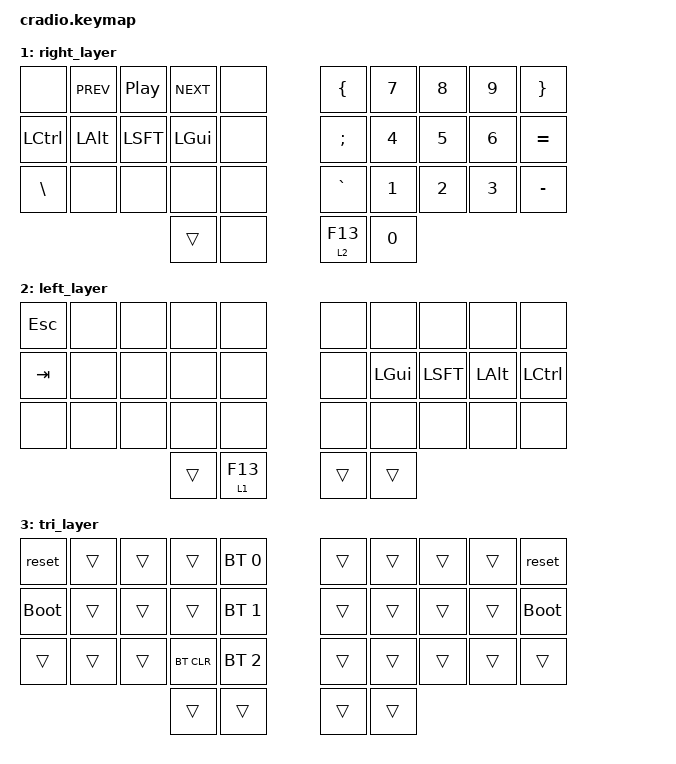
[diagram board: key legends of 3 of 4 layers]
// Copyright (c) 2022 The ZMK Contributors
// SPDX-License-Identifier: MIT

#include <behaviors.dtsi>
#include <dt-bindings/zmk/keys.h>
#include <dt-bindings/zmk/bt.h>

// Home row mods macro
#define HRML(k1,k2,k3,k4) &ht LCTRL k1  &ht LALT k2  &ht LSHFT k3  &ht LGUI k4
#define HRMR(k1,k2,k3,k4) &ht LGUI k1  &ht LSHFT k2  &ht LALT k3  &ht LCTRL k4

/ {
    behaviors {
        ht: hold_tap {
            label = "hold_tap";
            compatible = "zmk,behavior-hold-tap";
            #binding-cells = <2>;
            flavor = "tap-preferred";
            tapping-term-ms = <220>;
            quick-tap-ms = <150>;
            global-quick-tap;
            bindings = <&kp>, <&kp>;
        };
    };

    combos {
    	   compatible = "zmk,combos";
	   
 	   combo_coln {
	       key-positions = <20 21>;
	       bindings = <&kp COLON>;
	   };
 	   combo_mins {
	       key-positions = <22 23>;
	       bindings = <&kp MINUS>;
	   };
 	   combo_uscr {
	       key-positions = <26 27>;
	       bindings = <&kp UNDERSCORE>;
	   };
 	   combo_scln {
	       key-positions = <28 29>;
	       bindings = <&kp MINUS>;
	   };
	   
 	   combo_lbrc {
	       key-positions = <2 12>;
	       bindings = <&kp LBRC>;
	   };
 	   combo_lpar{
	       key-positions = <3 13>;
	       bindings = <&kp LPRN>;
	   };
 	   combo_lbkt {
	       key-positions = <4 14>;
	       bindings = <&kp LBKT>;
	   };
 	   combo_rbkt {
	       key-positions = <5 15>;
	       bindings = <&kp RBKT>;
	   };
 	   combo_rpar {
	       key-positions = <6 16>;
	       bindings = <&kp RPRN>;
	   };
 	   combo_rbrc {
	       key-positions = <7 17>;
	       bindings = <&kp RBRC>;
	   };
    };

    conditional_layers {
        compatible = "zmk,conditional-layers";
        tri_layer {
            if-layers = <1 2>;
            then-layer = <3>;
        };
    };

    keymap {
        compatible = "zmk,keymap";
        default_layer {
            bindings = <
        // //╭──────────┬──────────┬──────────┬──────────┬──────────╮   ╭──────────┬──────────┬──────────┬──────────┬──────────╮
        // //│  Q       │  W       │  E       │  R       │  T       │   │  Y       │  U       │  I       │  O       │  P       │
        //     &kp Q      &kp W      &kp E      &kp R      &kp T          &kp Y      &kp U      &kp I      &kp O      &kp P
        // //├──────────┼──────────┼──────────┼──────────┼──────────┤   ├──────────┼──────────┼──────────┼──────────┼──────────┤
        // //│  A       │  S       │  D       │  F       │  G       │   │  H       │  J       │  K       │  L       │ ' "      │
        //     HRML(A,        S,         D,         F)     &kp G          &kp H      HRMR(J,        K,         L,        SQT)
        // //├──────────┼──────────┼──────────┼──────────┼──────────┤   ├──────────┼──────────┼──────────┼──────────┼──────────┤
        // //│  Z       │  X       │  C       │  V       │  B       │   │  N       │  M       │ , <      │ . >      │ / ?      │
        //     &kp Z      &kp X      &kp C      &kp V      &kp B          &kp N      &kp M      &kp COMMA  &kp DOT    &kp FSLH
        // //╰──────────┴──────────┴──────────┼──────────┼──────────┤   ├──────────┼──────────┼──────────┴──────────┴──────────╯
        //                                     &kp LSHFT   &lt 1 BSPC    &lt 2 SPACE  &ht LALT ENTER
        // //                                 ╰──────────┴──────────╯   ╰──────────┴──────────╯

        //╭──────────┬──────────┬──────────┬──────────┬──────────╮   ╭──────────┬──────────┬──────────┬──────────┬──────────╮
            &kp Q      &kp W      &kp F      &kp P      &kp B          &kp J      &kp L      &kp U      &kp Y      &kp SQT
        //├──────────┼──────────┼──────────┼──────────┼──────────┤   ├──────────┼──────────┼──────────┼──────────┼──────────┤
            HRML(A,        R,         S,         T)     &kp G          &kp M      HRMR(N,        E,         I,        O)
        //├──────────┼──────────┼──────────┼──────────┼──────────┤   ├──────────┼──────────┼──────────┼──────────┼──────────┤
            &kp Z      &kp X      &kp C      &kp D      &kp V          &kp K      &kp H      &kp COMMA  &kp DOT    &kp FSLH
        //╰──────────┴──────────┴──────────┼──────────┼──────────┤   ├──────────┼──────────┼──────────┴──────────┴──────────╯
                                            &kp LSHFT   &lt 1 BSPC    &lt 2 SPACE  &ht LALT ENTER
        //                                 ╰──────────┴──────────╯   ╰──────────┴──────────╯
            >;
        };

        right_layer {
            bindings = <
        //╭──────────┬──────────┬──────────┬──────────┬──────────╮   ╭──────────┬──────────┬──────────┬──────────┬──────────╮
            &none      &kp C_PREV &kp C_PP   &kp C_NEXT &none          &kp LBRC   &kp N7     &kp N8     &kp N9     &kp RBRC
        //├──────────┼──────────┼──────────┼──────────┼──────────┤   ├──────────┼──────────┼──────────┼──────────┼──────────┤
            &kp LCTL   &kp LALT   &kp LSFT   &kp LGUI   &none          &kp SEMI   &kp N4     &kp N5     &kp N6     &kp EQUAL
        //├──────────┼──────────┼──────────┼──────────┼──────────┤   ├──────────┼──────────┼──────────┼──────────┼──────────┤
            &kp BSLH   &none      &none      &none      &none          &kp GRAVE  &kp N1     &kp N2     &kp N3     &kp MINUS
        //╰──────────┴──────────┴──────────┼──────────┼──────────┤   ├──────────┼──────────┼──────────┴──────────┴──────────╯
                                             &trans     &none          &lt 2 F13    &kp N0
        //                                 ╰──────────┴──────────╯   ╰──────────┴──────────╯
            >;
        };

        left_layer {
            bindings = <
        //╭──────────┬──────────┬──────────┬──────────┬──────────╮   ╭──────────┬──────────┬──────────┬──────────┬──────────╮
            &kp ESCAPE &none      &none      &none      &none          &none      &none      &none      &none      &none
        //├──────────┼──────────┼──────────┼──────────┼──────────┤   ├──────────┼──────────┼──────────┼──────────┼──────────┤
            &kp TAB    &none      &none      &none      &none          &none      &kp LGUI   &kp LSFT   &kp LALT   &kp LCTRL
        //├──────────┼──────────┼──────────┼──────────┼──────────┤   ├──────────┼──────────┼──────────┼──────────┼──────────┤
            &none      &none      &none      &none      &none          &none      &none      &none      &none      &none
        //╰──────────┴──────────┴──────────┼──────────┼──────────┤   ├──────────┼──────────┼──────────┴──────────┴──────────╯
                                             &trans     &lt 1 F13        &trans     &trans
        //                                 ╰──────────┴──────────╯   ╰──────────┴──────────╯
            >;
        };

        tri_layer {
            bindings = <
        //╭──────────┬──────────┬──────────┬──────────┬──────────╮   ╭──────────┬──────────┬──────────┬──────────┬──────────╮
        //│ RESET    │          │          │          │PROFILE 0 │   │          │          │          │          │  RESET   │
            &reset     &trans     &trans     &trans    &bt BT_SEL 0    &trans     &trans     &trans     &trans      &reset
        //├──────────┼──────────┼──────────┼──────────┼──────────┤   ├──────────┼──────────┼──────────┼──────────┼──────────┤
        //│BOOTLOADER│          │          │          │PROFILE 1 │   │          │          │          │          │BOOTLOADER│
          &bootloader  &trans     &trans     &trans    &bt BT_SEL 1    &trans     &trans     &trans     &trans    &bootloader
        //├──────────┼──────────┼──────────┼──────────┼──────────┤   ├──────────┼──────────┼──────────┼──────────┼──────────┤
        //│          │          │          │ CLEAR BT │PROFILE 2 │   │          │          │          │          │          │
            &trans     &trans     &trans    &bt BT_CLR &bt BT_SEL 2    &trans     &trans     &trans     &trans     &trans
        //╰──────────┴──────────┴──────────┼──────────┼──────────┤   ├──────────┼──────────┼──────────┴──────────┴──────────╯
                                             &trans     &trans         &trans     &trans
        //                                 ╰──────────┴──────────╯   ╰──────────┴──────────╯
            >;
        };
    };
};
